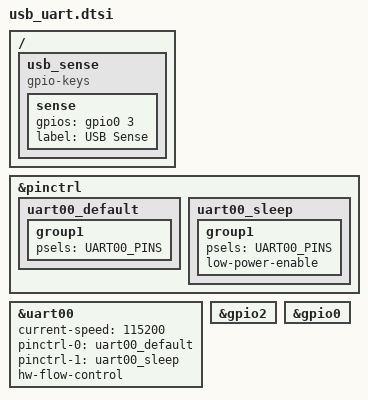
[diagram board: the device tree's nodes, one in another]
#define UART00_PINS \
	<NRF_PSEL(UART_TX, 2, 2)>, \
	<NRF_PSEL(UART_RX, 2, 0)>, \
	<NRF_PSEL(UART_RTS, 2, 5)>, \
	<NRF_PSEL(UART_CTS, 2, 4)>

&pinctrl {
	/omit-if-no-ref/ uart00_default: uart00_default {
		group1 {
			psels = UART00_PINS;
		};
	};

	/omit-if-no-ref/ uart00_sleep: uart00_sleep {
		group1 {
			psels = UART00_PINS;
			low-power-enable;
		};
	};
};


/ {
	usb_sense: usb_sense {
		compatible = "gpio-keys";
		sense: sense{
			gpios = <&gpio0 3 (GPIO_ACTIVE_HIGH | GPIO_PULL_DOWN)>;
			label = "USB Sense";
		};
	};
};

&uart00 { 
	status = "okay"; 
	current-speed = <115200>;
	pinctrl-0 = <&uart00_default>;
	pinctrl-1 = <&uart00_sleep>;
	pinctrl-names = "default", "sleep";
	hw-flow-control;
};

&gpio2 {
	status = "okay";
};

&gpio0 {
	status = "okay";
};
